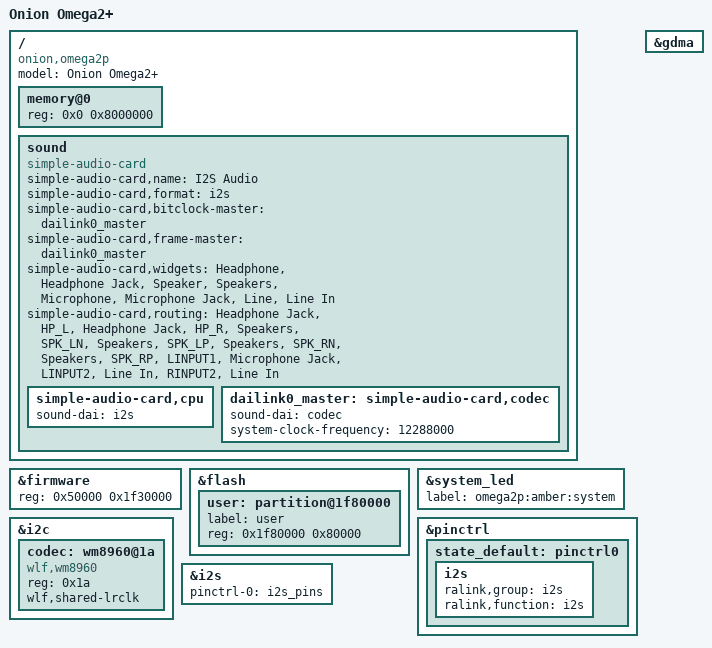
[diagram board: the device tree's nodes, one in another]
/dts-v1/;

#include "OMEGA2.dtsi"

/ {
	compatible = "onion,omega2p", "onion,omega2", "mediatek,mt7628an-soc";
	model = "Onion Omega2+";

	memory@0 {
		device_type = "memory";
		reg = <0x0 0x8000000>;
	};

	sound {
		compatible = "simple-audio-card";
		simple-audio-card,name = "I2S Audio";
		simple-audio-card,format = "i2s";
		simple-audio-card,bitclock-master = <&dailink0_master>;
		simple-audio-card,frame-master = <&dailink0_master>;

		simple-audio-card,widgets =
			"Headphone", "Headphone Jack",
			"Speaker", "Speakers",
			"Microphone", "Microphone Jack",
			"Line", "Line In";

		simple-audio-card,routing =
			"Headphone Jack", "HP_L",
			"Headphone Jack", "HP_R",
			"Speakers", "SPK_LN",
			"Speakers", "SPK_LP",
			"Speakers", "SPK_RN",
			"Speakers", "SPK_RP",
			"LINPUT1", "Microphone Jack",
			"LINPUT2", "Line In",
			"RINPUT2", "Line In";

		simple-audio-card,cpu {
			sound-dai = <&i2s>;
		};

		dailink0_master: simple-audio-card,codec {
			sound-dai = <&codec>;
			system-clock-frequency = <12288000>;
		};
	};



};

&firmware {
	reg = <0x50000 0x1f30000>;
};

&flash {
	user: partition@1f80000 {
		label = "user";
		reg = <0x1f80000 0x80000>;
	};
};

&system_led {
	label = "omega2p:amber:system";
};

&pinctrl {
	state_default: pinctrl0 {
		i2s {
			ralink,group = "i2s";
			ralink,function = "i2s";
		};
	};
};

&i2c {
 	status = "okay";

	codec: wm8960@1a {
		#sound-dai-cells = <0>;
		compatible = "wlf,wm8960";
		reg = <0x1a>;
		wlf,shared-lrclk;
	};
};

&i2s {
	#sound-dai-cells = <0>;
	status = "okay";
	pinctrl-names = "default";
	pinctrl-0 = <&i2s_pins>;
};

&gdma {
	status = "okay";
};
